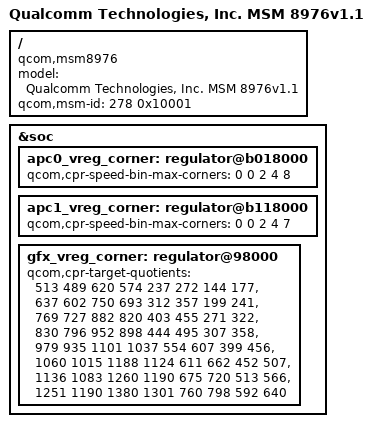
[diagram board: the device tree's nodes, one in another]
/*
 * Copyright (c) 2015, The Linux Foundation. All rights reserved.
 *
 * This program is free software; you can redistribute it and/or modify
 * it under the terms of the GNU General Public License version 2 and
 * only version 2 as published by the Free Software Foundation.
 *
 * This program is distributed in the hope that it will be useful,
 * but WITHOUT ANY WARRANTY; without even the implied warranty of
 * MERCHANTABILITY or FITNESS FOR A PARTICULAR PURPOSE.  See the
 * GNU General Public License for more details.
 */


/*
 * NOTE:
 * As a general rule, only version-specific property overrides should be placed
 * inside this file. However, device definitions should be placed inside the
 * msm8976.dtsi file.
 */

#include "msm8976.dtsi"

/ {
	model = "Qualcomm Technologies, Inc. MSM 8976v1.1";
	compatible = "qcom,msm8976";
	qcom,msm-id = <278 0x10001>;
};

/*Overwrite with V1.1 spec*/
&soc {
	/* APC0 / APC 1 / GFX CPR nodes */
	apc0_vreg_corner: regulator@b018000 {

		/delete-property/ qcom,cpr-fuse-version-map;
		/delete-property/ qcom,cpr-quotient-adjustment;

		qcom,cpr-speed-bin-max-corners =
				<0 0 2 4 8>;
	};

	apc1_vreg_corner: regulator@b118000 {

		/delete-property/ qcom,cpr-fuse-version-map;
		/delete-property/ qcom,cpr-quotient-adjustment;

		qcom,cpr-speed-bin-max-corners =
				<0 0 2 4 7>;
	};

	gfx_vreg_corner: regulator@98000 {
		qcom,cpr-target-quotients =
			<513  489  620  574  237 272 144 177>,
			<637  602  750  693  312 357 199 241>,
			<769  727  882  820  403 455 271 322>,
			<830  796  952  898  444 495 307 358>,
			<979  935  1101 1037 554 607 399 456>,
			<1060 1015 1188 1124 611 662 452 507>,
			<1136 1083 1260 1190 675 720 513 566>,
			<1251 1190 1380 1301 760 798 592 640>;
	};
};
